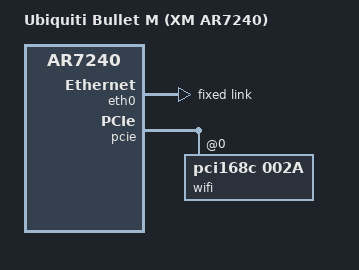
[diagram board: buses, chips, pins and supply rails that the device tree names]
// SPDX-License-Identifier: GPL-2.0-or-later OR MIT

#include "ar7240.dtsi"
#include "ar724x_ubnt_xm.dtsi"
#include "ar724x_ubnt_xm_outdoor.dtsi"

/ {
	compatible = "ubnt,bullet-m-ar7240", "ubnt,xm", "qca,ar7240";
	model = "Ubiquiti Bullet M (XM AR7240)";
};

&eth0 {
	fixed-link {
		speed = <100>;
		full-duplex;
	};
};

&eth1 {
	compatible = "syscon", "simple-mfd";
};

&art {
	cal_art_1000: calibration@1000 {
		reg = <0x1000 0xeb8>;
	};
};

&pcie {
	wifi: wifi@0,0 {
		compatible = "pci168c,002a";
		reg = <0x0000 0 0 0 0>;
		nvmem-cells = <&cal_art_1000>;
		nvmem-cell-names = "calibration";
	};
};
